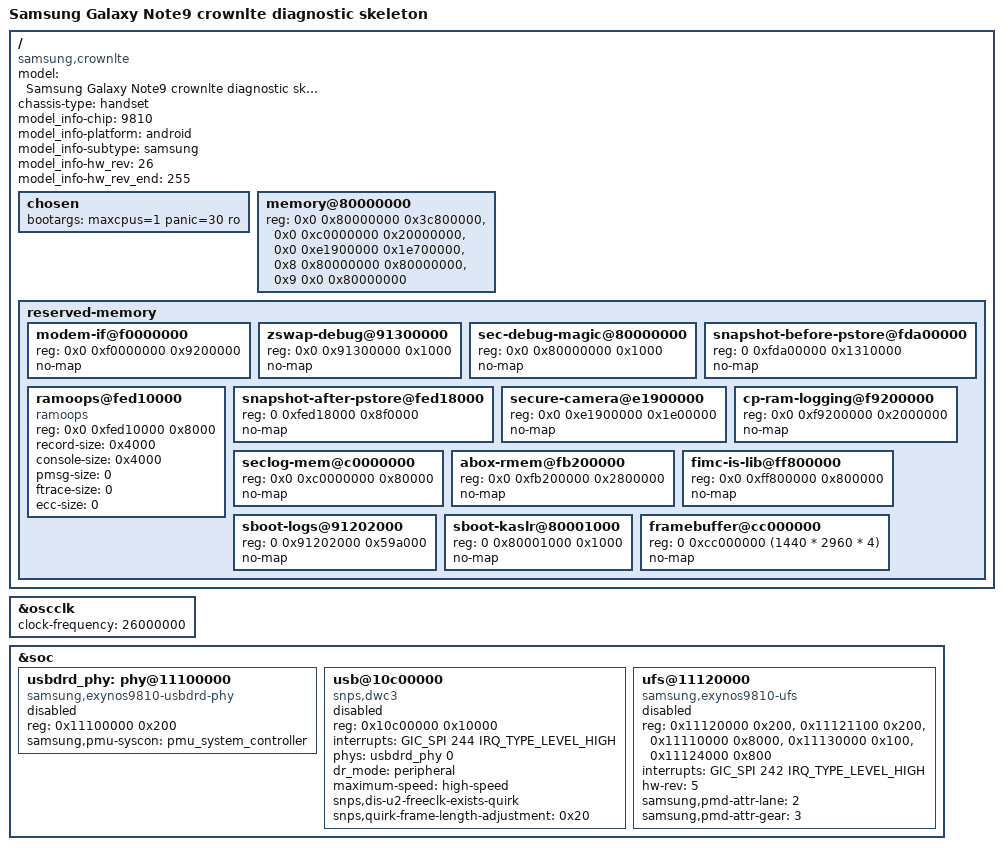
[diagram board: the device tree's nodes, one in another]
// SPDX-License-Identifier: GPL-2.0 OR BSD-3-Clause
/* Source-only Note9 diagnostic board skeleton. Not ready to flash.
 * Exynos9810 SoC definitions: Markuss Broks and Maksym Holovach.
 * Hardware identity from Samsung Crown rev0.6 downstream board DTS.
 * RAM and firmware reservations come from this device live DT capture.
 * Peripheral and bootloader handoff validation is still required.
 */
/dts-v1/;
#include "exynos9810.dtsi"

/ {
	model = "Samsung Galaxy Note9 crownlte diagnostic skeleton";
	compatible = "samsung,crownlte", "samsung,exynos9810";
	chassis-type = "handset";
	model_info-chip = <9810>;
	model_info-platform = "android";
	model_info-subtype = "samsung";
	model_info-hw_rev = <26>;
	model_info-hw_rev_end = <255>;
	chosen {
		bootargs = "maxcpus=1 panic=30 ro";
	};
};

&oscclk { clock-frequency = <26000000>; };

/ {
	memory@80000000 {
		device_type = "memory";
		reg = <0x0 0x80000000 0x3c800000>,
		      <0x0 0xc0000000 0x20000000>,
		      <0x0 0xe1900000 0x1e700000>,
		      <0x8 0x80000000 0x80000000>,
		      <0x9 0x0 0x80000000>;
	};
	reserved-memory {
		#address-cells = <2>;
		#size-cells = <1>;
		ranges;
		modem-if@f0000000 {
			reg = <0x0 0xf0000000 0x9200000>;
			no-map;
		};
		zswap-debug@91300000 {
			reg = <0x0 0x91300000 0x1000>;
			no-map;
		};
		sec-debug-magic@80000000 {
			reg = <0x0 0x80000000 0x1000>;
			no-map;
		};
		snapshot-before-pstore@fda00000 {
			reg = <0 0xfda00000 0x1310000>;
			no-map;
		};
		ramoops@fed10000 {
			compatible = "ramoops";
			reg = <0x0 0xfed10000 0x8000>;
			record-size = <0x4000>;
			console-size = <0x4000>;
			pmsg-size = <0>;
			ftrace-size = <0>;
			ecc-size = <0>;
		};
		snapshot-after-pstore@fed18000 {
			reg = <0 0xfed18000 0x8f0000>;
			no-map;
		};
		secure-camera@e1900000 {
			reg = <0x0 0xe1900000 0x1e00000>;
			no-map;
		};
		cp-ram-logging@f9200000 {
			reg = <0x0 0xf9200000 0x2000000>;
			no-map;
		};
		seclog-mem@c0000000 {
			reg = <0x0 0xc0000000 0x80000>;
			no-map;
		};
		abox-rmem@fb200000 {
			reg = <0x0 0xfb200000 0x2800000>;
			no-map;
		};
		fimc-is-lib@ff800000 {
			reg = <0x0 0xff800000 0x800000>;
			no-map;
		};
		sboot-logs@91202000 {
			reg = <0 0x91202000 0x59a000>;
			no-map;
		};
		sboot-kaslr@80001000 {
			reg = <0 0x80001000 0x1000>;
			no-map;
		};
		framebuffer@cc000000 {
			reg = <0 0xcc000000 (1440 * 2960 * 4)>;
			no-map;
		};
	};
};

/* Register mappings verified against this phone's live DT. Peripheral clock
 * providers, pad routing and power setup are still incomplete. Keep disabled.
 */
&soc {
	usbdrd_phy: phy@11100000 {
		compatible = "samsung,exynos9810-usbdrd-phy";
		reg = <0x11100000 0x200>;
		samsung,pmu-syscon = <&pmu_system_controller>;
		#phy-cells = <1>;
		status = "disabled";
	};
	usb@10c00000 {
		compatible = "snps,dwc3";
		reg = <0x10c00000 0x10000>;
		interrupts = <GIC_SPI 244 IRQ_TYPE_LEVEL_HIGH>;
		phys = <&usbdrd_phy 0>;
		phy-names = "usb2-phy";
		dr_mode = "peripheral";
		maximum-speed = "high-speed";
		snps,dis-u2-freeclk-exists-quirk;
		snps,quirk-frame-length-adjustment = <0x20>;
		status = "disabled";
	};
	ufs@11120000 {
		compatible = "samsung,exynos9810-ufs";
		reg = <0x11120000 0x200>, <0x11121100 0x200>,
		      <0x11110000 0x8000>, <0x11130000 0x100>,
		      <0x11124000 0x800>;
		reg-names = "hci", "vs_hci", "unipro", "ufsp", "pma";
		interrupts = <GIC_SPI 242 IRQ_TYPE_LEVEL_HIGH>;
		hw-rev = <5>;
		samsung,pmd-attr-lane = /bits/ 8 <2>;
		samsung,pmd-attr-gear = /bits/ 8 <3>;
		status = "disabled";
	};
};
